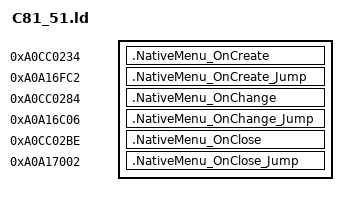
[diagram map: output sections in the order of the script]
SECTIONS {
    .NativeMenu_OnCreate 0xA0CC0234 : {
        KEEP(*(.text.NativeMenu_OnCreate))
    }
    .NativeMenu_OnCreate_Jump 0xA0A16FC2 : {
        KEEP(*(.text.NativeMenu_OnCreate_Jump))
    }

    .NativeMenu_OnChange 0xA0CC0284 : {
        KEEP(*(.text.NativeMenu_OnChange))
        KEEP(*(.rodata*))
    }
    .NativeMenu_OnChange_Jump 0xA0A16C06 : {
        KEEP(*(.text.NativeMenu_OnChange_Jump))
    }

    .NativeMenu_OnClose 0xA0CC02BE : {
        KEEP(*(.text.NativeMenu_OnClose))
    }
    .NativeMenu_OnClose_Jump 0xA0A17002 : {
        KEEP(*(.text.NativeMenu_OnClose_Jump))
    }
}
